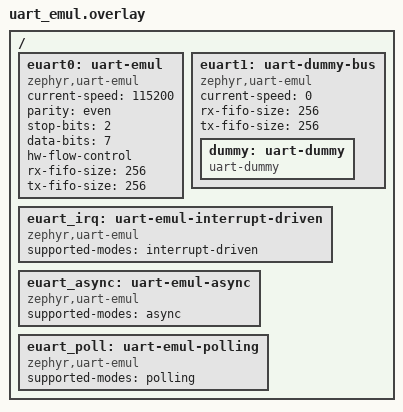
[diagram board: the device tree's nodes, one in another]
/*
 * Copyright (c) 2023 Fabian Blatz
 *
 * SPDX-License-Identifier: Apache-2.0
 */

/ {
	euart0: uart-emul {
		compatible = "zephyr,uart-emul";
		current-speed = <115200>;
		parity = "even";
		stop-bits = "2";
		data-bits = <7>;
		hw-flow-control;
		rx-fifo-size = <256>;
		tx-fifo-size = <256>;
		status = "okay";
	};

	euart1: uart-dummy-bus {
		compatible = "zephyr,uart-emul";
		current-speed = <0>;
		rx-fifo-size = <256>;
		tx-fifo-size = <256>;
		status = "okay";

		dummy: uart-dummy {
			compatible = "uart-dummy";
			status = "okay";
		};
	};

	euart_irq: uart-emul-interrupt-driven {
		compatible = "zephyr,uart-emul";
		supported-modes = "interrupt-driven";
		status = "okay";
	};

	euart_async: uart-emul-async {
		compatible = "zephyr,uart-emul";
		supported-modes = "async";
		status = "okay";
	};

	euart_poll: uart-emul-polling {
		compatible = "zephyr,uart-emul";
		supported-modes = "polling";
		status = "okay";
	};
};
